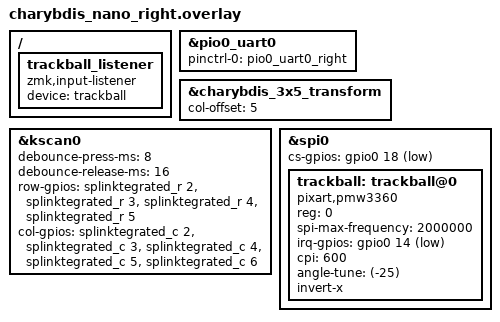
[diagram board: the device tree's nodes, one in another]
#include "charybdis_nano.dtsi"

&pio0_uart0 {
    pinctrl-0 = <&pio0_uart0_right>;
};

&charybdis_3x5_transform {
    col-offset = <5>;
};

// TODO: trim kscan
&kscan0 {
    debounce-press-ms = <8>;
    debounce-release-ms = <16>;
    row-gpios
        = <&splinktegrated_r 2 GPIO_ACTIVE_HIGH>
        , <&splinktegrated_r 3 GPIO_ACTIVE_HIGH>
        , <&splinktegrated_r 4 GPIO_ACTIVE_HIGH>
        , <&splinktegrated_r 5 GPIO_ACTIVE_HIGH>
        ;

    col-gpios
        = <&splinktegrated_c 2 (GPIO_ACTIVE_HIGH | GPIO_PULL_DOWN)>
        , <&splinktegrated_c 3 (GPIO_ACTIVE_HIGH | GPIO_PULL_DOWN)>
        , <&splinktegrated_c 4 (GPIO_ACTIVE_HIGH | GPIO_PULL_DOWN)>
        , <&splinktegrated_c 5 (GPIO_ACTIVE_HIGH | GPIO_PULL_DOWN)>
        , <&splinktegrated_c 6 (GPIO_ACTIVE_HIGH | GPIO_PULL_DOWN)>
        ;
};

/* PMW3360 Trackball */
&spi0 {
    status = "okay";
    cs-gpios = <&gpio0 18 GPIO_ACTIVE_LOW>;

    trackball: trackball@0 {
        compatible = "pixart,pmw3360";
        status = "okay";
        reg = <0>;
        spi-max-frequency = <2000000>;
        irq-gpios = <&gpio0 14 (GPIO_ACTIVE_LOW | GPIO_PULL_UP)>;
        cpi = <600>;
        angle-tune = <(-25)>;
        invert-x;
    };
};

/ {
    trackball_listener {
        compatible = "zmk,input-listener";
        device = <&trackball>;
    };
};
